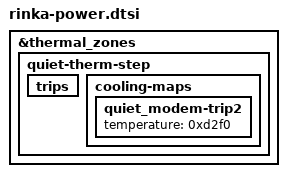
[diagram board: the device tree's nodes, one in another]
&thermal_zones {

	quiet-therm-step {

		trips {

			/delete-node/ quiet_batt-trip1;
			/delete-node/ quiet_batt-trip2;
			/delete-node/ quiet_batt-trip3;
			/delete-node/ quiet_batt-trip4;
		};

		cooling-maps {

			/delete-node/ battery_lvl1;
			/delete-node/ battery_lvl2;
			/delete-node/ battery_lvl3;
			/delete-node/ battery_lvl4;

			quiet_modem-trip2 {

				/delete-property/ temperature;

				temperature = <0xd2f0>;
			};
		};
	};
};
